# dwc_uciephy_top: IP-XACT component
VLNV Synopsys:DesignWareCores:dwc_uciephy_top:1.00

## Address spaces and blocks
regmap_UCIE.UCIEMMPLSECTION0: base 'h1000, range 'h10, width 32
regmap_UCIE.UCIEDWORDSECTION0_0: base 'h1010, range 'ha0, width 32
regmap_UCIE.UCIEDWORDSECTION0_1: base 'h11010, range 'ha0, width 32

## Registers
Registers are 32-bit, read-write, reset 0x0 unless marked. A register's access mark holds for its fields unless they carry their own. Offsets are from the block's base; lines under a group give offsets from that group; [hi:lo] are bit positions; {n}, {i} and the like mark numbered series; 'fields as' and 'values as' point back to an identical list; <NAME> marks a mode.

## regmap_UCIE.UCIEMMPLSECTION0 — UCIeMMPLSECTION0 Block Registers
Base 0x00001000
0x00 UciePhyCapabilty ro reset 0x8868 — UCIe PHY capability.
  [16:0] UciePhyCapabilty
0x04 UciePhyControl reset 0x8
  [6:0] UciePhyControl
0x08 UciePhyStatus ro reset 0x8
  [7:0] UciePhyStatus
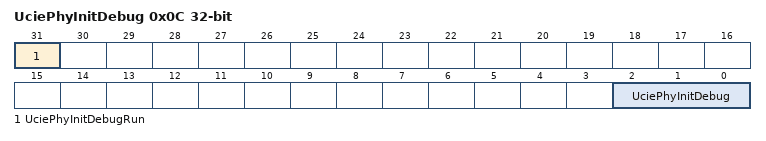
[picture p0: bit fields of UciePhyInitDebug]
0x0C UciePhyInitDebug — UCIe PHY initialization and debug.
  [31] UciePhyInitDebugRun write-clears — Triggers this debug-mode initialization. Starts running until to the LTSM state specified in AcsmLtsmDebugState
  [2:0] UciePhyInitDebug — UCIe PHY initialization and debug.

## regmap_UCIE.UCIEDWORDSECTION0_0 — UCIeDWORDSECTION0 Block Registers
Base 0x00001010
Same registers: regmap_UCIE.UCIEDWORDSECTION0_1 0x00011010
0x00 UcieTrainingSetup1 reset 0x800000
  [26:0] UcieTrainingSetup1
0x10 UcieTrainingSetup2 reset 0x10000
0x20 UcieTrainingSetup3Lwr — UCIe training setup 3.
0x24 UcieTrainingSetup3Upr — UCIe training setup 3.
0x40 UcieTrainingSetup4
0x50 UcieCurrentLaneMapLwr — UCIe current lane map.
0x54 UcieCurrentLaneMapUpr — UCIe current lane map.
0x70 UcieErrorLog0 ro
0x80 UcieErrorLog1 ro
